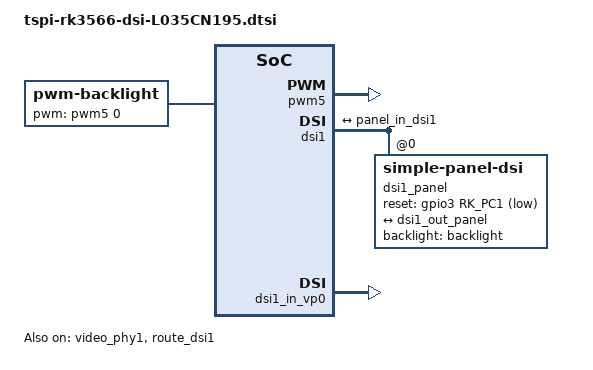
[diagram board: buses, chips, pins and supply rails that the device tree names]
/********************************************************************
 * SPDX-License-Identifier: (GPL-2.0+ OR MIT)
 *
 * Copyright (c) 2023 Rockchip Electronics Co., Ltd.
 * Copyright (c) 2026 LCKFB <lckfb@sz-jlc.com>
 *********************************************************************
 * Wiki-(Chinese)：https://wiki.lckfb.com/
 * Wiki-(English)：https://wiki.lckfb.com/en/
 *********************************************************************/
/ {
	backlight: backlight {
		compatible = "pwm-backlight";
		pwms = <&pwm5 0 25000 0>;
		brightness-levels = <
			  0  20  20  21  21  22  22  23
			 23  24  24  25  25  26  26  27
			 27  28  28  29  29  30  30  31
			 31  32  32  33  33  34  34  35
			 35  36  36  37  37  38  38  39
			 40  41  42  43  44  45  46  47
			 48  49  50  51  52  53  54  55
			 56  57  58  59  60  61  62  63
			 64  65  66  67  68  69  70  71
			 72  73  74  75  76  77  78  79
			 80  81  82  83  84  85  86  87
			 88  89  90  91  92  93  94  95
			 96  97  98  99 100 101 102 103
			104 105 106 107 108 109 110 111
			112 113 114 115 116 117 118 119
			120 121 122 123 124 125 126 127
			128 129 130 131 132 133 134 135
			136 137 138 139 140 141 142 143
			144 145 146 147 148 149 150 151
			152 153 154 155 156 157 158 159
			160 161 162 163 164 165 166 167
			168 169 170 171 172 173 174 175
			176 177 178 179 180 181 182 183
			184 185 186 187 188 189 190 191
			192 193 194 195 196 197 198 199
			200 201 202 203 204 205 206 207
			208 209 210 211 212 213 214 215
			216 217 218 219 220 221 222 223
			224 225 226 227 228 229 230 231
			232 233 234 235 236 237 238 239
			240 241 242 243 244 245 246 247
			248 249 250 251 252 253 254 255
		>;
		default-brightness-level = <255>;
	};
};

&pwm5 {
	status = "okay";
};

&pinctrl {
	dsi1 {
		dsi1_rst_gpio: dsi1-rst-gpio {
			rockchip,pins = <3 RK_PC1 RK_FUNC_GPIO &pcfg_pull_none>;
		};
	};
};

/*
 * video_phy1 needs to be enabled
 * when dsi1 is enabled
 */
&dsi1 {
	status = "okay";
};

&dsi1_in_vp0 {
	status = "okay";
};

&dsi1_in_vp1 {
	status = "disabled";
};

&video_phy1 {
	status = "okay";
};

&route_dsi1 {
	status = "okay";
	connect = <&vp0_out_dsi1>;
};

// L035CN195-A 3.5 inch 640x480 MIPI panel, FL7703N
&dsi1 {
	status = "okay";
	rockchip,lane-rate = <300>;
	dsi1_panel: panel@0 {
		status = "okay";

		compatible = "simple-panel-dsi";
		reset-gpios = <&gpio3 RK_PC1 GPIO_ACTIVE_LOW>;

		pinctrl-names = "default";
		pinctrl-0 = <&dsi1_rst_gpio>;
		reg = <0>;
		backlight = <&backlight>;
		width-mm = <70>;
		height-mm = <53>;
		reset-delay-ms = <20>;
		enable-delay-ms = <20>;
		prepare-delay-ms = <120>;
		unprepare-delay-ms = <120>;
		disable-delay-ms = <50>;
		init-delay-ms = <120>;
		dsi,flags = <(MIPI_DSI_MODE_VIDEO | MIPI_DSI_MODE_VIDEO_BURST |
			MIPI_DSI_MODE_LPM)>;
		dsi,format = <MIPI_DSI_FMT_RGB888>;
		dsi,lanes  = <4>;
		panel-init-sequence = [
			39 00 04 B9 F1 12 87
			39 00 04 B2 78 04 70
			39 00 0B B3 10 10 FC FC 03 FF 00 00 00 00
			15 00 02 B4 80
			39 00 03 B5 0F 0F
			39 00 03 B6 70 70
			39 00 05 B8 26 22 F0 13
			39 00 1C BA 33 81 05 F9 0E 0E 20 00 00 00 00 00 00 00 44 25 00 91 0A 00 00 01 4F 01 00 00 37
			15 00 02 BC 47
			39 00 06 BF 02 11 00 80 04
			39 00 0A C0 73 73 50 50 00 00 12 73 00
			39 00 12 C1 73 00 32 32 77 F4 77 77 CC CC FF FF 11 11 00 00 32
			39 00 0D C7 B8 00 0A 10 01 09 00 00 ED C5 00 A5
			39 00 05 C8 10 40 1E 03
			15 00 02 CC 0B
			39 00 23 E0 00 05 09 29 3C 3F 3B 37 05 0A 0C 10 13 10 13 12 1A 00 05 09 29 3C 3F 3B 37 05 0A 0C 10 13 10 13 12 1A
			39 00 08 E1 11 11 91 00 00 00 00
			39 00 0F E3 07 07 0B 0B 0B 0B 00 00 00 00 FF 04 C0 10
			39 00 40 E9 C8 10 02 00 00 B0 B1 11 31 23 28 80 B0 B1 27 08 00 04 02 00 00 00 00 04 02 00 00 00 88 88 BA 60 24 08 88 88 88 88 88 88 88 BA 71 35 18 88 88 88 88 88 00 00 00 01 00 00 00 00 00 00 00 00 00
			39 00 3E EA 97 0A 82 02 03 07 00 00 00 00 00 00 81 88 BA 17 53 88 88 88 88 88 88 80 88 BA 06 42 88 88 88 88 88 88 23 00 00 02 A5 00 00 00 00 00 00 00 00 00 00 00 00 00 00 00 00 00 00 00 00 00 00
			39 00 04 EF FF FF 01
			05 78 01 11
			05 0A 01 29
		];

		panel-exit-sequence = [
			05 00 01 28
			05 00 01 10
		];

		disp_timings1: display-timings {
			native-mode = <&dsi1_timing0>;
			dsi1_timing0: timing0 {
				clock-frequency = <36864000>;
				hactive = <640>;
				vactive = <480>;
				hfront-porch = <117>;
				hsync-len = <110>;
				hback-porch = <110>;
				vfront-porch = <16>;
				vsync-len = <4>;
				vback-porch = <12>;
				hsync-active = <0>;
				vsync-active = <0>;
				de-active = <0>;
				pixelclk-active = <0>;
			};
		};

		ports {
			#address-cells = <1>;
			#size-cells = <0>;

			port@0 {
				reg = <0>;
				panel_in_dsi1: endpoint {
					remote-endpoint = <&dsi1_out_panel>;
				};
			};
		};
	};

	ports {
		#address-cells = <1>;
		#size-cells = <0>;

		port@1 {
			reg = <1>;
			dsi1_out_panel: endpoint {
				remote-endpoint = <&panel_in_dsi1>;
			};
		};
	};
};
